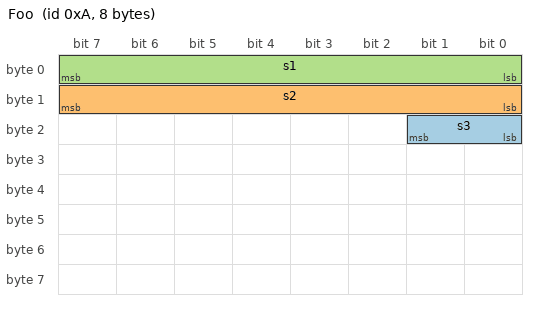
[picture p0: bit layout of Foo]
BO_ 10 Foo: 8 Vector__XXX
 SG_ s3 : 16|2@1+ (1,0) [0|0] "" Vector__XXX
 SG_ s2 : 8|8@1+ (1,0) [0|0] "" Vector__XXX
 SG_ s1 : 0|8@1+ (1,0) [0|0] "" Vector__XXX
